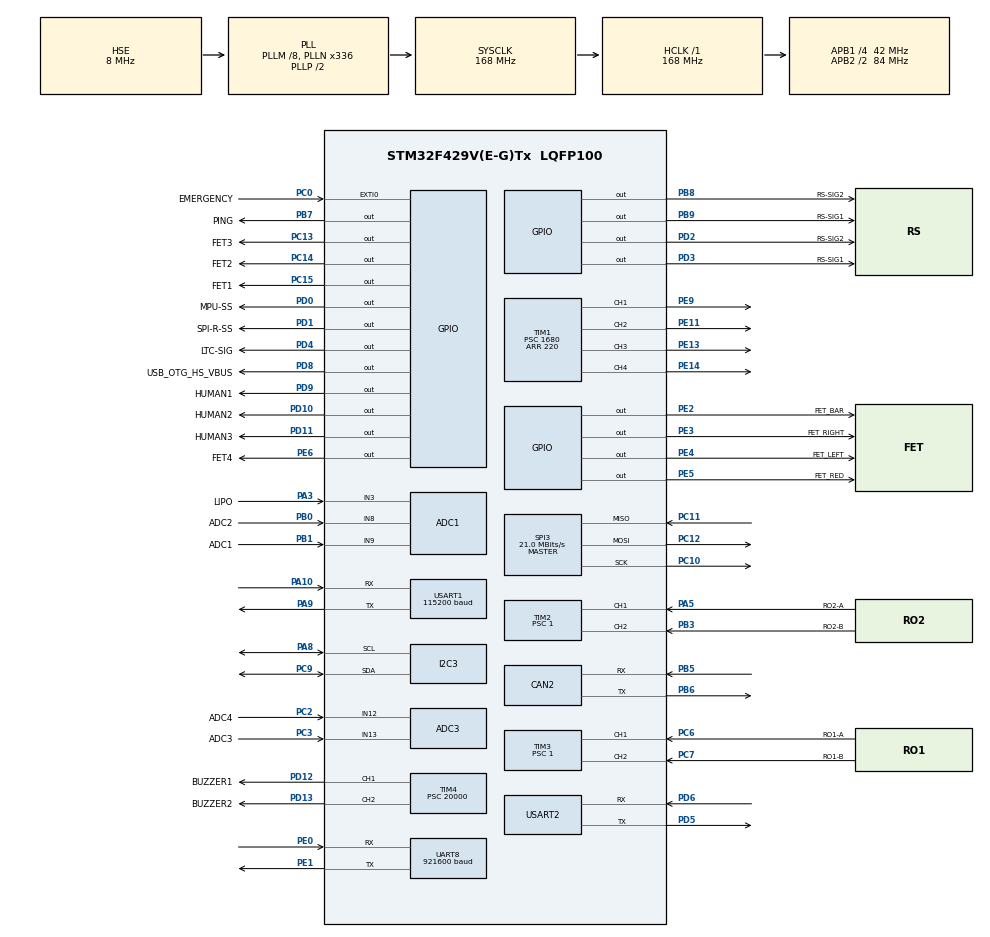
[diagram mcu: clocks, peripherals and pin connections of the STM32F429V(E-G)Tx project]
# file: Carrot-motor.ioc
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ADC1.Channel-3\#ChannelRegularConversion=ADC_CHANNEL_3
ADC1.Channel-6\#ChannelRegularConversion=ADC_CHANNEL_9
ADC1.ClockPrescaler=ADC_CLOCK_SYNC_PCLK_DIV4
ADC1.ContinuousConvMode=ENABLE
ADC1.DMAContinuousRequests=ENABLE
ADC1.InjNumberOfConversion=0
ADC1.NbrOfConversion=2
ADC1.NbrOfConversionFlag=1
ADC1.Rank-3\#ChannelRegularConversion=1
ADC1.Rank-6\#ChannelRegularConversion=2
ADC1.SamplingTime-3\#ChannelRegularConversion=ADC_SAMPLETIME_480CYCLES
ADC1.SamplingTime-6\#ChannelRegularConversion=ADC_SAMPLETIME_480CYCLES
ADC1.ScanConvMode=ENABLE
ADC1.master=1
ADC3.Channel-0\#ChannelRegularConversion=ADC_CHANNEL_12
ADC3.ClockPrescaler=ADC_CLOCK_SYNC_PCLK_DIV4
ADC3.NbrOfConversionFlag=1
ADC3.Rank-0\#ChannelRegularConversion=1
ADC3.SamplingTime-0\#ChannelRegularConversion=ADC_SAMPLETIME_3CYCLES
CAN2.BS1=CAN_BS1_1TQ
CAN2.BS2=CAN_BS2_1TQ
CAN2.CalculateTimeQuantum=380.95238095238096
Dma.ADC1.0.Direction=DMA_PERIPH_TO_MEMORY
Dma.ADC1.0.FIFOMode=DMA_FIFOMODE_DISABLE
Dma.ADC1.0.Instance=DMA2_Stream0
Dma.ADC1.0.MemDataAlignment=DMA_MDATAALIGN_HALFWORD
Dma.ADC1.0.MemInc=DMA_MINC_ENABLE
Dma.ADC1.0.Mode=DMA_CIRCULAR
Dma.ADC1.0.PeriphDataAlignment=DMA_PDATAALIGN_HALFWORD
Dma.ADC1.0.PeriphInc=DMA_PINC_DISABLE
Dma.ADC1.0.Priority=DMA_PRIORITY_HIGH
Dma.Request0=ADC1
Dma.Request1=UART8_RX
Dma.UART8_RX.1.Direction=DMA_PERIPH_TO_MEMORY
Dma.UART8_RX.1.FIFOMode=DMA_FIFOMODE_DISABLE
Dma.UART8_RX.1.Instance=DMA1_Stream6
Dma.UART8_RX.1.MemDataAlignment=DMA_MDATAALIGN_HALFWORD
Dma.UART8_RX.1.MemInc=DMA_MINC_ENABLE
Dma.UART8_RX.1.Mode=DMA_CIRCULAR
Dma.UART8_RX.1.PeriphDataAlignment=DMA_PDATAALIGN_HALFWORD
Dma.UART8_RX.1.PeriphInc=DMA_PINC_DISABLE
Dma.UART8_RX.1.Priority=DMA_PRIORITY_HIGH
FREERTOS.HEAP_NUMBER=4
FREERTOS.INCLUDE_uxTaskGetStackHighWaterMark=1
FREERTOS.INCLUDE_vTaskDelayUntil=1
FREERTOS.MEMORY_ALLOCATION=2
FREERTOS.Tasks01=defaultTask,8,128,StartDefaultTask,Default,NULL,Static,defaultTaskBuffer,defaultTaskControlBlock;adc1,8,1024,check_adc1_task,As external,NULL,Static,adc1Buffer,adc1ControlBlock;motor,8,1024,motor_task,As external,NULL,Static,motorBuffer,motorControlBlock;EMERGENCY,8,1024,EMERGENCY_notification,As external,NULL,Static,EMERGENCYBuffer,EMERGENCYControlBlock;encoder,48,128,encoder_task,As external,NULL,Static,encoderBuffer,encoderControlBlock;led,8,1024,led_task,As external,NULL,Static,LED_taskBuffer,LED_taskControlBlock
FREERTOS.configUSE_IDLE_HOOK=1
FREERTOS.configUSE_STATS_FORMATTING_FUNCTIONS=1
FREERTOS.configUSE_TRACE_FACILITY=1
Mcu.Family=STM32F4
Mcu.Name=STM32F429V(E-G)Tx
Mcu.Package=LQFP100
NVIC.DMA1_Stream6_IRQn=true\:5\:0\:false\:false\:true\:true\:false\:true
NVIC.DMA2_Stream0_IRQn=true\:5\:0\:false\:false\:true\:true\:false\:true
NVIC.EXTI0_IRQn=true\:2\:0\:true\:false\:true\:false\:true\:true
NVIC.PriorityGroup=NVIC_PRIORITYGROUP_4
NVIC.TIM1_UP_TIM10_IRQn=true\:5\:0\:false\:false\:true\:true\:true\:true
NVIC.TIM8_TRG_COM_TIM14_IRQn=true\:0\:0\:false\:false\:true\:false\:false\:true
NVIC.TIM8_UP_TIM13_IRQn=true\:5\:0\:false\:false\:true\:true\:true\:true
NVIC.TimeBase=TIM8_TRG_COM_TIM14_IRQn
NVIC.TimeBaseIP=TIM14
NVIC.UART8_IRQn=true\:1\:0\:true\:false\:true\:false\:true\:true
PA10.Mode=Asynchronous
PA10.Signal=USART1_RX
PA13.Mode=Serial_Wire
PA13.Signal=SYS_JTMS-SWDIO
PA14.Mode=Serial_Wire
PA14.Signal=SYS_JTCK-SWCLK
PA3.GPIO_Label=LIPO
PA3.Signal=ADCx_IN3
PA5.GPIO_Label=RO2-A
PA5.GPIO_Speed=GPIO_SPEED_FREQ_VERY_HIGH
PA5.Signal=S_TIM2_CH1_ETR
PA8.Mode=I2C
PA8.Signal=I2C3_SCL
PA9.Mode=Asynchronous
PA9.Signal=USART1_TX
PB0.GPIO_Label=ADC2
PB0.Signal=ADCx_IN8
PB1.GPIO_Label=ADC1
PB1.Signal=ADCx_IN9
PB14.Signal=USB_OTG_HS_DM
PB15.Signal=USB_OTG_HS_DP
PB3.GPIO_Label=RO2-B
PB3.GPIO_Speed=GPIO_SPEED_FREQ_VERY_HIGH
PB3.Signal=S_TIM2_CH2
PB5.Mode=Slave
PB5.Signal=CAN2_RX
PB6.Mode=Slave
PB6.Signal=CAN2_TX
PB7.GPIO_Label=PING
PB7.Signal=GPIO_Output
PB8.GPIO_Label=RS-SIG2
PB8.Signal=GPIO_Output
PB9.GPIO_Label=RS-SIG1
PB9.Signal=GPIO_Output
PC0.GPIO_Label=EMERGENCY
PC0.GPIO_ModeDefaultEXTI=GPIO_MODE_IT_RISING_FALLING
PC0.Signal=GPXTI0
PC10.Mode=Full_Duplex_Master
PC10.Signal=SPI3_SCK
PC11.Mode=Full_Duplex_Master
PC11.Signal=SPI3_MISO
PC12.Mode=Full_Duplex_Master
PC12.Signal=SPI3_MOSI
PC13.GPIO_Label=FET3
PC13.GPIO_PuPd=GPIO_NOPULL
PC13.PinState=GPIO_PIN_SET
PC13.Signal=GPIO_Output
PC14/OSC32_IN.GPIO_Label=FET2
PC14/OSC32_IN.GPIO_PuPd=GPIO_NOPULL
PC14/OSC32_IN.PinState=GPIO_PIN_SET
PC14/OSC32_IN.Signal=GPIO_Output
PC15/OSC32_OUT.GPIO_Label=FET1
PC15/OSC32_OUT.GPIO_PuPd=GPIO_NOPULL
PC15/OSC32_OUT.PinState=GPIO_PIN_SET
PC15/OSC32_OUT.Signal=GPIO_Output
PC2.GPIO_Label=ADC4
PC2.Signal=ADCx_IN12
PC3.GPIO_Label=ADC3
PC3.Signal=ADCx_IN13
PC6.GPIO_Label=RO1-A
PC6.GPIO_Speed=GPIO_SPEED_FREQ_VERY_HIGH
PC6.Signal=S_TIM3_CH1
PC7.GPIO_Label=RO1-B
PC7.GPIO_Speed=GPIO_SPEED_FREQ_VERY_HIGH
PC7.Signal=S_TIM3_CH2
PC9.Mode=I2C
PC9.Signal=I2C3_SDA
PD0.GPIO_Label=MPU-SS
PD0.Signal=GPIO_Output
PD1.GPIO_Label=SPI-R-SS
PD1.Signal=GPIO_Output
PD10.GPIO_Label=HUMAN2
PD10.Signal=GPIO_Output
PD11.GPIO_Label=HUMAN3
PD11.Signal=GPIO_Output
PD12.GPIO_Label=BUZZER1
PD12.Signal=S_TIM4_CH1
PD13.GPIO_Label=BUZZER2
PD13.Signal=S_TIM4_CH2
PD2.GPIO_Label=RS-SIG2
PD2.Signal=GPIO_Output
PD3.GPIO_Label=RS-SIG1
PD3.Signal=GPIO_Output
PD4.GPIO_Label=LTC-SIG
PD4.Signal=GPIO_Output
PD5.Mode=Asynchronous
PD5.Signal=USART2_TX
PD6.Mode=Asynchronous
PD6.Signal=USART2_RX
PD8.GPIO_Label=USB_OTG_HS_VBUS
PD8.Signal=GPIO_Output
PD9.GPIO_Label=HUMAN1
PD9.Signal=GPIO_Output
PE0.Mode=Asynchronous
PE0.Signal=UART8_RX
PE1.Mode=Asynchronous
PE1.Signal=UART8_TX
PE11.Signal=S_TIM1_CH2
PE13.Signal=S_TIM1_CH3
PE14.Signal=S_TIM1_CH4
PE2.GPIO_Label=FET_BAR
PE2.PinState=GPIO_PIN_SET
PE2.Signal=GPIO_Output
PE3.GPIO_Label=FET_RIGHT
PE3.PinState=GPIO_PIN_SET
PE3.Signal=GPIO_Output
PE4.GPIO_Label=FET_LEFT
PE4.PinState=GPIO_PIN_SET
PE4.Signal=GPIO_Output
PE5.GPIO_Label=FET_RED
PE5.PinState=GPIO_PIN_SET
PE5.Signal=GPIO_Output
PE6.GPIO_Label=FET4
PE6.GPIO_Speed=GPIO_SPEED_FREQ_VERY_HIGH
PE6.PinState=GPIO_PIN_SET
PE6.Signal=GPIO_Output
PE9.GPIO_Speed=GPIO_SPEED_FREQ_LOW
PE9.Signal=S_TIM1_CH1
PH0/OSC_IN.Mode=HSE-External-Oscillator
PH0/OSC_IN.Signal=RCC_OSC_IN
PH1/OSC_OUT.Mode=HSE-External-Oscillator
PH1/OSC_OUT.Signal=RCC_OSC_OUT
ProjectManager.HeapSize=0x200
ProjectManager.StackSize=0x400
ProjectManager.TargetToolchain=STM32CubeIDE
RCC.48MHZClocksFreq_Value=48000000
RCC.AHBFreq_Value=168000000
RCC.APB1CLKDivider=RCC_HCLK_DIV4
RCC.APB1Freq_Value=42000000
RCC.APB1TimFreq_Value=84000000
RCC.APB2CLKDivider=RCC_HCLK_DIV2
RCC.APB2Freq_Value=84000000
RCC.APB2TimFreq_Value=168000000
RCC.CortexFreq_Value=168000000
RCC.HCLKFreq_Value=168000000
RCC.HSE_VALUE=8000000
RCC.HSI_VALUE=16000000
RCC.LSE_VALUE=32768
RCC.PLLM=8
RCC.PLLN=336
RCC.PLLQ=7
RCC.PLLSourceVirtual=RCC_PLLSOURCE_HSE
RCC.SYSCLKFreq_VALUE=168000000
RCC.SYSCLKSource=RCC_SYSCLKSOURCE_PLLCLK
RCC.VCOOutputFreq_Value=336000000
SH.ADCx_IN12.0=ADC3_IN12,IN12
SH.ADCx_IN13.0=ADC3_IN13,IN13
SH.ADCx_IN3.0=ADC1_IN3,IN3
SH.ADCx_IN8.0=ADC1_IN8,IN8
SH.ADCx_IN9.0=ADC1_IN9,IN9
SH.S_TIM1_CH1.0=TIM1_CH1,PWM Generation1 CH1
SH.S_TIM1_CH2.0=TIM1_CH2,PWM Generation2 CH2
SH.S_TIM1_CH3.0=TIM1_CH3,PWM Generation3 CH3
SH.S_TIM1_CH4.0=TIM1_CH4,PWM Generation4 CH4
SH.S_TIM2_CH1_ETR.0=TIM2_CH1,Encoder_Interface
SH.S_TIM2_CH2.0=TIM2_CH2,Encoder_Interface
SH.S_TIM3_CH1.0=TIM3_CH1,Encoder_Interface
SH.S_TIM3_CH2.0=TIM3_CH2,Encoder_Interface
SH.S_TIM4_CH1.0=TIM4_CH1,PWM Generation1 CH1
SH.S_TIM4_CH2.0=TIM4_CH2,PWM Generation2 CH2
SPI3.BaudRatePrescaler=SPI_BAUDRATEPRESCALER_2
SPI3.CalculateBaudRate=21.0 MBits/s
SPI3.Direction=SPI_DIRECTION_2LINES
SPI3.Mode=SPI_MODE_MASTER
SPI3.VirtualType=VM_MASTER
TIM1.Channel-PWM\ Generation1\ CH1=TIM_CHANNEL_1
TIM1.Channel-PWM\ Generation2\ CH2=TIM_CHANNEL_2
TIM1.Channel-PWM\ Generation3\ CH3=TIM_CHANNEL_3
TIM1.Channel-PWM\ Generation4\ CH4=TIM_CHANNEL_4
TIM1.Period=220
TIM1.Prescaler=1680
TIM10.Period=1
TIM10.Prescaler=0
TIM13.Period=1
TIM13.Prescaler=0
TIM2.Period=65535
TIM2.Prescaler=1
TIM3.AutoReloadPreload=TIM_AUTORELOAD_PRELOAD_DISABLE
TIM3.Period=65535
TIM3.Prescaler=1
TIM3.TIM_MasterOutputTrigger=TIM_TRGO_RESET
TIM3.TIM_MasterSlaveMode=TIM_MASTERSLAVEMODE_DISABLE
TIM4.Channel-PWM\ Generation1\ CH1=TIM_CHANNEL_1
TIM4.Channel-PWM\ Generation2\ CH2=TIM_CHANNEL_2
TIM4.ClockDivision=TIM_CLOCKDIVISION_DIV1
TIM4.Period=10
TIM4.Prescaler=20000
UART8.BaudRate=921600
UART8.VirtualMode=Asynchronous
USART1.BaudRate=115200
USART1.Parity=PARITY_NONE
USART1.VirtualMode=VM_ASYNC
USART2.VirtualMode=VM_ASYNC
VP_FREERTOS_VS_CMSIS_V2.Mode=CMSIS_V2
VP_SYS_VS_tim14.Mode=TIM14
VP_TIM10_VS_ClockSourceINT.Mode=Enable_Timer
VP_TIM13_VS_ClockSourceINT.Mode=Enable_Timer
board=custom

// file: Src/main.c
/* USER CODE BEGIN Header */
/**
  ******************************************************************************
  * @file           : main.c
  * @brief          : Main program body
  ******************************************************************************
  * @attention
  *
  * <h2><center>&copy; Copyright (c) 2019 STMicroelectronics.
  * All rights reserved.</center></h2>
  *
  * This software component is licensed by ST under BSD 3-Clause license,
  * the "License"; You may not use this file except in compliance with the
  * License. You may obtain a copy of the License at:
  *                        opensource.org/licenses/BSD-3-Clause
  *
  ******************************************************************************
  */
/* USER CODE END Header */

#include "main.h"
#include "cmsis_os.h"

/* USER CODE BEGIN Includes */
#include "source/carrot_adc_control.hpp"
#include "source/carrot_wrapper.hpp"
#include "source/interrupt.hpp"
#include "source/motor_control.hpp"
/* USER CODE END Includes */

typedef StaticTask_t osStaticThreadDef_t;

ADC_HandleTypeDef hadc1;
ADC_HandleTypeDef hadc3;
DMA_HandleTypeDef hdma_adc1;

CAN_HandleTypeDef hcan2;

I2C_HandleTypeDef hi2c3;

SPI_HandleTypeDef hspi3;

TIM_HandleTypeDef htim1;
TIM_HandleTypeDef htim2;
TIM_HandleTypeDef htim3;
TIM_HandleTypeDef htim4;
TIM_HandleTypeDef htim10;
TIM_HandleTypeDef htim13;

UART_HandleTypeDef huart8;
UART_HandleTypeDef huart1;
UART_HandleTypeDef huart2;
DMA_HandleTypeDef hdma_uart8_rx;

/* Definitions for defaultTask */
osThreadId_t defaultTaskHandle;
uint32_t defaultTaskBuffer[ 128 ];
osStaticThreadDef_t defaultTaskControlBlock;
const osThreadAttr_t defaultTask_attributes = {
  .name = "defaultTask",
  .stack_mem = &defaultTaskBuffer[0],
  .stack_size = sizeof(defaultTaskBuffer),
  .cb_mem = &defaultTaskControlBlock,
  .cb_size = sizeof(defaultTaskControlBlock),
  .priority = (osPriority_t) osPriorityLow,
};
/* Definitions for adc1 */
osThreadId_t adc1Handle;
uint32_t adc1Buffer[ 1024 ];
osStaticThreadDef_t adc1ControlBlock;
const osThreadAttr_t adc1_attributes = {
  .name = "adc1",
  .stack_mem = &adc1Buffer[0],
  .stack_size = sizeof(adc1Buffer),
  .cb_mem = &adc1ControlBlock,
  .cb_size = sizeof(adc1ControlBlock),
  .priority = (osPriority_t) osPriorityLow,
};
/* Definitions for motor */
osThreadId_t motorHandle;
uint32_t motorBuffer[ 1024 ];
osStaticThreadDef_t motorControlBlock;
const osThreadAttr_t motor_attributes = {
  .name = "motor",
  .stack_mem = &motorBuffer[0],
  .stack_size = sizeof(motorBuffer),
  .cb_mem = &motorControlBlock,
  .cb_size = sizeof(motorControlBlock),
  .priority = (osPriority_t) osPriorityLow,
};
/* Definitions for EMERGENCY */
osThreadId_t EMERGENCYHandle;
uint32_t EMERGENCYBuffer[ 1024 ];
osStaticThreadDef_t EMERGENCYControlBlock;
const osThreadAttr_t EMERGENCY_attributes = {
  .name = "EMERGENCY",
  .stack_mem = &EMERGENCYBuffer[0],
  .stack_size = sizeof(EMERGENCYBuffer),
  .cb_mem = &EMERGENCYControlBlock,
  .cb_size = sizeof(EMERGENCYControlBlock),
  .priority = (osPriority_t) osPriorityLow,
};
/* Definitions for encoder */
osThreadId_t encoderHandle;
uint32_t encoderBuffer[ 128 ];
osStaticThreadDef_t encoderControlBlock;
const osThreadAttr_t encoder_attributes = {
  .name = "encoder",
  .stack_mem = &encoderBuffer[0],
  .stack_size = sizeof(encoderBuffer),
  .cb_mem = &encoderControlBlock,
  .cb_size = sizeof(encoderControlBlock),
  .priority = (osPriority_t) osPriorityRealtime,
};
/* Definitions for led */
osThreadId_t ledHandle;
uint32_t LED_taskBuffer[ 1024 ];
osStaticThreadDef_t LED_taskControlBlock;
const osThreadAttr_t led_attributes = {
  .name = "led",
  .stack_mem = &LED_taskBuffer[0],
  .stack_size = sizeof(LED_taskBuffer),
  .cb_mem = &LED_taskControlBlock,
  .cb_size = sizeof(LED_taskControlBlock),
  .priority = (osPriority_t) osPriorityLow,
};

void SystemClock_Config(void);
static void MX_GPIO_Init(void);
static void MX_DMA_Init(void);
static void MX_USART1_UART_Init(void);
static void MX_USART2_UART_Init(void);
static void MX_CAN2_Init(void);
static void MX_SPI3_Init(void);
static void MX_TIM1_Init(void);
static void MX_TIM2_Init(void);
static void MX_ADC1_Init(void);
static void MX_ADC3_Init(void);
static void MX_TIM3_Init(void);
static void MX_TIM4_Init(void);
static void MX_UART8_Init(void);
static void MX_I2C3_Init(void);
static void MX_TIM13_Init(void);
static void MX_TIM10_Init(void);
void StartDefaultTask(void *argument);
extern void check_adc1_task(void *argument);
extern void motor_task(void *argument);
extern void EMERGENCY_notification(void *argument);
extern void encoder_task(void *argument);
extern void led_task(void *argument);

/* USER CODE BEGIN 0 */
void HAL_UART_RxCpltCallback(UART_HandleTypeDef *UartHandle)
{
     /*if(UartHandle->Instance==UART8){
    	 raspi_uart_func();
    }*/
}

/* USER CODE END 0 */

int main(void)
{

  /* MCU Configuration--------------------------------------------------------*/

  /* Reset of all peripherals, Initializes the Flash interface and the Systick. */
  HAL_Init();

  /* Configure the system clock */
  SystemClock_Config();

  /* Initialize all configured peripherals */
  MX_GPIO_Init();
  MX_DMA_Init();
  MX_USART1_UART_Init();
  MX_USART2_UART_Init();
  MX_CAN2_Init();
  MX_SPI3_Init();
  MX_TIM1_Init();
  MX_TIM2_Init();
  MX_ADC1_Init();
  MX_ADC3_Init();
  MX_TIM3_Init();
  MX_TIM4_Init();
  MX_UART8_Init();
  MX_I2C3_Init();
  MX_TIM13_Init();
  MX_TIM10_Init();
  /* USER CODE BEGIN 2 */
  init_carrot();

  /* USER CODE END 2 */
  /* Init scheduler */
  osKernelInitialize();

  /* Create the thread(s) */
  /* creation of defaultTask */
  defaultTaskHandle = osThreadNew(StartDefaultTask, NULL, &defaultTask_attributes);

  /* creation of adc1 */
  adc1Handle = osThreadNew(check_adc1_task, NULL, &adc1_attributes);

  /* creation of motor */
  motorHandle = osThreadNew(motor_task, NULL, &motor_attributes);

  /* creation of EMERGENCY */
  EMERGENCYHandle = osThreadNew(EMERGENCY_notification, NULL, &EMERGENCY_attributes);

  /* creation of encoder */
  encoderHandle = osThreadNew(encoder_task, NULL, &encoder_attributes);

  /* creation of led */
  ledHandle = osThreadNew(led_task, NULL, &led_attributes);

  /* Start scheduler */
  osKernelStart();

  /* We should never get here as control is now taken by the scheduler */

  /* Infinite loop */
  while (1)
  {

  }
}

void SystemClock_Config(void)
{
  RCC_OscInitTypeDef RCC_OscInitStruct = {0};
  RCC_ClkInitTypeDef RCC_ClkInitStruct = {0};

  /** Configure the main internal regulator output voltage
  */
  __HAL_RCC_PWR_CLK_ENABLE();
  __HAL_PWR_VOLTAGESCALING_CONFIG(PWR_REGULATOR_VOLTAGE_SCALE1);
  /** Initializes the CPU, AHB and APB busses clocks
  */
  RCC_OscInitStruct.OscillatorType = RCC_OSCILLATORTYPE_HSE;
  RCC_OscInitStruct.HSEState = RCC_HSE_ON;
  RCC_OscInitStruct.PLL.PLLState = RCC_PLL_ON;
  RCC_OscInitStruct.PLL.PLLSource = RCC_PLLSOURCE_HSE;
  RCC_OscInitStruct.PLL.PLLM = 8;
  RCC_OscInitStruct.PLL.PLLN = 336;
  RCC_OscInitStruct.PLL.PLLP = RCC_PLLP_DIV2;
  RCC_OscInitStruct.PLL.PLLQ = 7;
  if (HAL_RCC_OscConfig(&RCC_OscInitStruct) != HAL_OK)
  {
    Error_Handler();
  }
  /** Initializes the CPU, AHB and APB busses clocks
  */
  RCC_ClkInitStruct.ClockType = RCC_CLOCKTYPE_HCLK|RCC_CLOCKTYPE_SYSCLK
                              |RCC_CLOCKTYPE_PCLK1|RCC_CLOCKTYPE_PCLK2;
  RCC_ClkInitStruct.SYSCLKSource = RCC_SYSCLKSOURCE_PLLCLK;
  RCC_ClkInitStruct.AHBCLKDivider = RCC_SYSCLK_DIV1;
  RCC_ClkInitStruct.APB1CLKDivider = RCC_HCLK_DIV4;
  RCC_ClkInitStruct.APB2CLKDivider = RCC_HCLK_DIV2;

  if (HAL_RCC_ClockConfig(&RCC_ClkInitStruct, FLASH_LATENCY_5) != HAL_OK)
  {
    Error_Handler();
  }
}

static void MX_ADC1_Init(void)
{

  ADC_ChannelConfTypeDef sConfig = {0};

  /** Configure the global features of the ADC (Clock, Resolution, Data Alignment and number of conversion)
  */
  hadc1.Instance = ADC1;
  hadc1.Init.ClockPrescaler = ADC_CLOCK_SYNC_PCLK_DIV4;
  hadc1.Init.Resolution = ADC_RESOLUTION_12B;
  hadc1.Init.ScanConvMode = ENABLE;
  hadc1.Init.ContinuousConvMode = ENABLE;
  hadc1.Init.DiscontinuousConvMode = DISABLE;
  hadc1.Init.ExternalTrigConvEdge = ADC_EXTERNALTRIGCONVEDGE_NONE;
  hadc1.Init.ExternalTrigConv = ADC_SOFTWARE_START;
  hadc1.Init.DataAlign = ADC_DATAALIGN_RIGHT;
  hadc1.Init.NbrOfConversion = 2;
  hadc1.Init.DMAContinuousRequests = ENABLE;
  hadc1.Init.EOCSelection = ADC_EOC_SINGLE_CONV;
  if (HAL_ADC_Init(&hadc1) != HAL_OK)
  {
    Error_Handler();
  }
  /** Configure for the selected ADC regular channel its corresponding rank in the sequencer and its sample time.
  */
  sConfig.Channel = ADC_CHANNEL_3;
  sConfig.Rank = 1;
  sConfig.SamplingTime = ADC_SAMPLETIME_480CYCLES;
  if (HAL_ADC_ConfigChannel(&hadc1, &sConfig) != HAL_OK)
  {
    Error_Handler();
  }
  /** Configure for the selected ADC regular channel its corresponding rank in the sequencer and its sample time.
  */
  sConfig.Channel = ADC_CHANNEL_9;
  sConfig.Rank = 2;
  if (HAL_ADC_ConfigChannel(&hadc1, &sConfig) != HAL_OK)
  {
    Error_Handler();
  }

}

static void MX_ADC3_Init(void)
{

  ADC_ChannelConfTypeDef sConfig = {0};

  /** Configure the global features of the ADC (Clock, Resolution, Data Alignment and number of conversion)
  */
  hadc3.Instance = ADC3;
  hadc3.Init.ClockPrescaler = ADC_CLOCK_SYNC_PCLK_DIV4;
  hadc3.Init.Resolution = ADC_RESOLUTION_12B;
  hadc3.Init.ScanConvMode = DISABLE;
  hadc3.Init.ContinuousConvMode = DISABLE;
  hadc3.Init.DiscontinuousConvMode = DISABLE;
  hadc3.Init.ExternalTrigConvEdge = ADC_EXTERNALTRIGCONVEDGE_NONE;
  hadc3.Init.ExternalTrigConv = ADC_SOFTWARE_START;
  hadc3.Init.DataAlign = ADC_DATAALIGN_RIGHT;
  hadc3.Init.NbrOfConversion = 1;
  hadc3.Init.DMAContinuousRequests = DISABLE;
  hadc3.Init.EOCSelection = ADC_EOC_SINGLE_CONV;
  if (HAL_ADC_Init(&hadc3) != HAL_OK)
  {
    Error_Handler();
  }
  /** Configure for the selected ADC regular channel its corresponding rank in the sequencer and its sample time.
  */
  sConfig.Channel = ADC_CHANNEL_12;
  sConfig.Rank = 1;
  sConfig.SamplingTime = ADC_SAMPLETIME_3CYCLES;
  if (HAL_ADC_ConfigChannel(&hadc3, &sConfig) != HAL_OK)
  {
    Error_Handler();
  }

}

static void MX_CAN2_Init(void)
{

  hcan2.Instance = CAN2;
  hcan2.Init.Prescaler = 16;
  hcan2.Init.Mode = CAN_MODE_NORMAL;
  hcan2.Init.SyncJumpWidth = CAN_SJW_1TQ;
  hcan2.Init.TimeSeg1 = CAN_BS1_1TQ;
  hcan2.Init.TimeSeg2 = CAN_BS2_1TQ;
  hcan2.Init.TimeTriggeredMode = DISABLE;
  hcan2.Init.AutoBusOff = DISABLE;
  hcan2.Init.AutoWakeUp = DISABLE;
  hcan2.Init.AutoRetransmission = DISABLE;
  hcan2.Init.ReceiveFifoLocked = DISABLE;
  hcan2.Init.TransmitFifoPriority = DISABLE;
  if (HAL_CAN_Init(&hcan2) != HAL_OK)
  {
    Error_Handler();
  }

}

static void MX_I2C3_Init(void)
{

  hi2c3.Instance = I2C3;
  hi2c3.Init.ClockSpeed = 100000;
  hi2c3.Init.DutyCycle = I2C_DUTYCYCLE_2;
  hi2c3.Init.OwnAddress1 = 0;
  hi2c3.Init.AddressingMode = I2C_ADDRESSINGMODE_7BIT;
  hi2c3.Init.DualAddressMode = I2C_DUALADDRESS_DISABLE;
  hi2c3.Init.OwnAddress2 = 0;
  hi2c3.Init.GeneralCallMode = I2C_GENERALCALL_DISABLE;
  hi2c3.Init.NoStretchMode = I2C_NOSTRETCH_DISABLE;
  if (HAL_I2C_Init(&hi2c3) != HAL_OK)
  {
    Error_Handler();
  }
  /** Configure Analogue filter
  */
  if (HAL_I2CEx_ConfigAnalogFilter(&hi2c3, I2C_ANALOGFILTER_ENABLE) != HAL_OK)
  {
    Error_Handler();
  }
  /** Configure Digital filter
  */
  if (HAL_I2CEx_ConfigDigitalFilter(&hi2c3, 0) != HAL_OK)
  {
    Error_Handler();
  }

}

static void MX_SPI3_Init(void)
{

  /* SPI3 parameter configuration*/
  hspi3.Instance = SPI3;
  hspi3.Init.Mode = SPI_MODE_MASTER;
  hspi3.Init.Direction = SPI_DIRECTION_2LINES;
  hspi3.Init.DataSize = SPI_DATASIZE_8BIT;
  hspi3.Init.CLKPolarity = SPI_POLARITY_LOW;
  hspi3.Init.CLKPhase = SPI_PHASE_1EDGE;
  hspi3.Init.NSS = SPI_NSS_SOFT;
  hspi3.Init.BaudRatePrescaler = SPI_BAUDRATEPRESCALER_2;
  hspi3.Init.FirstBit = SPI_FIRSTBIT_MSB;
  hspi3.Init.TIMode = SPI_TIMODE_DISABLE;
  hspi3.Init.CRCCalculation = SPI_CRCCALCULATION_DISABLE;
  hspi3.Init.CRCPolynomial = 10;
  if (HAL_SPI_Init(&hspi3) != HAL_OK)
  {
    Error_Handler();
  }

}

static void MX_TIM1_Init(void)
{

  TIM_MasterConfigTypeDef sMasterConfig = {0};
  TIM_OC_InitTypeDef sConfigOC = {0};
  TIM_BreakDeadTimeConfigTypeDef sBreakDeadTimeConfig = {0};

  htim1.Instance = TIM1;
  htim1.Init.Prescaler = 1680;
  htim1.Init.CounterMode = TIM_COUNTERMODE_UP;
  htim1.Init.Period = 220;
  htim1.Init.ClockDivision = TIM_CLOCKDIVISION_DIV1;
  htim1.Init.RepetitionCounter = 0;
  htim1.Init.AutoReloadPreload = TIM_AUTORELOAD_PRELOAD_DISABLE;
  if (HAL_TIM_PWM_Init(&htim1) != HAL_OK)
  {
    Error_Handler();
  }
  sMasterConfig.MasterOutputTrigger = TIM_TRGO_RESET;
  sMasterConfig.MasterSlaveMode = TIM_MASTERSLAVEMODE_DISABLE;
  if (HAL_TIMEx_MasterConfigSynchronization(&htim1, &sMasterConfig) != HAL_OK)
  {
    Error_Handler();
  }
  sConfigOC.OCMode = TIM_OCMODE_PWM1;
  sConfigOC.Pulse = 0;
  sConfigOC.OCPolarity = TIM_OCPOLARITY_HIGH;
  sConfigOC.OCNPolarity = TIM_OCNPOLARITY_HIGH;
  sConfigOC.OCFastMode = TIM_OCFAST_DISABLE;
  sConfigOC.OCIdleState = TIM_OCIDLESTATE_RESET;
  sConfigOC.OCNIdleState = TIM_OCNIDLESTATE_RESET;
  if (HAL_TIM_PWM_ConfigChannel(&htim1, &sConfigOC, TIM_CHANNEL_1) != HAL_OK)
  {
    Error_Handler();
  }
  if (HAL_TIM_PWM_ConfigChannel(&htim1, &sConfigOC, TIM_CHANNEL_2) != HAL_OK)
  {
    Error_Handler();
  }
  if (HAL_TIM_PWM_ConfigChannel(&htim1, &sConfigOC, TIM_CHANNEL_3) != HAL_OK)
  {
    Error_Handler();
  }
  if (HAL_TIM_PWM_ConfigChannel(&htim1, &sConfigOC, TIM_CHANNEL_4) != HAL_OK)
  {
    Error_Handler();
  }
  sBreakDeadTimeConfig.OffStateRunMode = TIM_OSSR_DISABLE;
  sBreakDeadTimeConfig.OffStateIDLEMode = TIM_OSSI_DISABLE;
  sBreakDeadTimeConfig.LockLevel = TIM_LOCKLEVEL_OFF;
  sBreakDeadTimeConfig.DeadTime = 0;
  sBreakDeadTimeConfig.BreakState = TIM_BREAK_DISABLE;
  sBreakDeadTimeConfig.BreakPolarity = TIM_BREAKPOLARITY_HIGH;
  sBreakDeadTimeConfig.AutomaticOutput = TIM_AUTOMATICOUTPUT_DISABLE;
  if (HAL_TIMEx_ConfigBreakDeadTime(&htim1, &sBreakDeadTimeConfig) != HAL_OK)
  {
    Error_Handler();
  }
  HAL_TIM_MspPostInit(&htim1);

}

static void MX_TIM2_Init(void)
{

  TIM_Encoder_InitTypeDef sConfig = {0};
  TIM_MasterConfigTypeDef sMasterConfig = {0};

  htim2.Instance = TIM2;
  htim2.Init.Prescaler = 1;
  htim2.Init.CounterMode = TIM_COUNTERMODE_UP;
  htim2.Init.Period = 65535;
  htim2.Init.ClockDivision = TIM_CLOCKDIVISION_DIV1;
  htim2.Init.AutoReloadPreload = TIM_AUTORELOAD_PRELOAD_DISABLE;
  sConfig.EncoderMode = TIM_ENCODERMODE_TI1;
  sConfig.IC1Polarity = TIM_ICPOLARITY_RISING;
  sConfig.IC1Selection = TIM_ICSELECTION_DIRECTTI;
  sConfig.IC1Prescaler = TIM_ICPSC_DIV1;
  sConfig.IC1Filter = 0;
  sConfig.IC2Polarity = TIM_ICPOLARITY_RISING;
  sConfig.IC2Selection = TIM_ICSELECTION_DIRECTTI;
  sConfig.IC2Prescaler = TIM_ICPSC_DIV1;
  sConfig.IC2Filter = 0;
  if (HAL_TIM_Encoder_Init(&htim2, &sConfig) != HAL_OK)
  {
    Error_Handler();
  }
  sMasterConfig.MasterOutputTrigger = TIM_TRGO_RESET;
  sMasterConfig.MasterSlaveMode = TIM_MASTERSLAVEMODE_DISABLE;
  if (HAL_TIMEx_MasterConfigSynchronization(&htim2, &sMasterConfig) != HAL_OK)
  {
    Error_Handler();
  }

}

static void MX_TIM3_Init(void)
{

  TIM_Encoder_InitTypeDef sConfig = {0};
  TIM_MasterConfigTypeDef sMasterConfig = {0};

  htim3.Instance = TIM3;
  htim3.Init.Prescaler = 1;
  htim3.Init.CounterMode = TIM_COUNTERMODE_UP;
  htim3.Init.Period = 65535;
  htim3.Init.ClockDivision = TIM_CLOCKDIVISION_DIV1;
  htim3.Init.AutoReloadPreload = TIM_AUTORELOAD_PRELOAD_DISABLE;
  sConfig.EncoderMode = TIM_ENCODERMODE_TI1;
  sConfig.IC1Polarity = TIM_ICPOLARITY_RISING;
  sConfig.IC1Selection = TIM_ICSELECTION_DIRECTTI;
  sConfig.IC1Prescaler = TIM_ICPSC_DIV1;
  sConfig.IC1Filter = 0;
  sConfig.IC2Polarity = TIM_ICPOLARITY_RISING;
  sConfig.IC2Selection = TIM_ICSELECTION_DIRECTTI;
  sConfig.IC2Prescaler = TIM_ICPSC_DIV1;
  sConfig.IC2Filter = 0;
  if (HAL_TIM_Encoder_Init(&htim3, &sConfig) != HAL_OK)
  {
    Error_Handler();
  }
  sMasterConfig.MasterOutputTrigger = TIM_TRGO_RESET;
  sMasterConfig.MasterSlaveMode = TIM_MASTERSLAVEMODE_DISABLE;
  if (HAL_TIMEx_MasterConfigSynchronization(&htim3, &sMasterConfig) != HAL_OK)
  {
    Error_Handler();
  }

}

static void MX_TIM4_Init(void)
{

  TIM_MasterConfigTypeDef sMasterConfig = {0};
  TIM_OC_InitTypeDef sConfigOC = {0};

  htim4.Instance = TIM4;
  htim4.Init.Prescaler = 20000;
  htim4.Init.CounterMode = TIM_COUNTERMODE_UP;
  htim4.Init.Period = 10;
  htim4.Init.ClockDivision = TIM_CLOCKDIVISION_DIV1;
  htim4.Init.AutoReloadPreload = TIM_AUTORELOAD_PRELOAD_DISABLE;
  if (HAL_TIM_PWM_Init(&htim4) != HAL_OK)
  {
    Error_Handler();
  }
  sMasterConfig.MasterOutputTrigger = TIM_TRGO_RESET;
  sMasterConfig.MasterSlaveMode = TIM_MASTERSLAVEMODE_DISABLE;
  if (HAL_TIMEx_MasterConfigSynchronization(&htim4, &sMasterConfig) != HAL_OK)
  {
    Error_Handler();
  }
  sConfigOC.OCMode = TIM_OCMODE_PWM1;
  sConfigOC.Pulse = 0;
  sConfigOC.OCPolarity = TIM_OCPOLARITY_HIGH;
  sConfigOC.OCFastMode = TIM_OCFAST_DISABLE;
  if (HAL_TIM_PWM_ConfigChannel(&htim4, &sConfigOC, TIM_CHANNEL_1) != HAL_OK)
  {
    Error_Handler();
  }
  if (HAL_TIM_PWM_ConfigChannel(&htim4, &sConfigOC, TIM_CHANNEL_2) != HAL_OK)
  {
    Error_Handler();
  }
  HAL_TIM_MspPostInit(&htim4);

}

static void MX_TIM10_Init(void)
{

  htim10.Instance = TIM10;
  htim10.Init.Prescaler = 0;
  htim10.Init.CounterMode = TIM_COUNTERMODE_UP;
  htim10.Init.Period = 1;
  htim10.Init.ClockDivision = TIM_CLOCKDIVISION_DIV1;
  htim10.Init.AutoReloadPreload = TIM_AUTORELOAD_PRELOAD_DISABLE;
  if (HAL_TIM_Base_Init(&htim10) != HAL_OK)
  {
    Error_Handler();
  }

}

static void MX_TIM13_Init(void)
{

  htim13.Instance = TIM13;
  htim13.Init.Prescaler = 0;
  htim13.Init.CounterMode = TIM_COUNTERMODE_UP;
  htim13.Init.Period = 1;
  htim13.Init.ClockDivision = TIM_CLOCKDIVISION_DIV1;
  htim13.Init.AutoReloadPreload = TIM_AUTORELOAD_PRELOAD_DISABLE;
  if (HAL_TIM_Base_Init(&htim13) != HAL_OK)
  {
    Error_Handler();
  }

}

static void MX_UART8_Init(void)
{

  huart8.Instance = UART8;
  huart8.Init.BaudRate = 921600;
  huart8.Init.WordLength = UART_WORDLENGTH_8B;
  huart8.Init.StopBits = UART_STOPBITS_1;
  huart8.Init.Parity = UART_PARITY_NONE;
  huart8.Init.Mode = UART_MODE_TX_RX;
  huart8.Init.HwFlowCtl = UART_HWCONTROL_NONE;
  huart8.Init.OverSampling = UART_OVERSAMPLING_16;
  if (HAL_UART_Init(&huart8) != HAL_OK)
  {
    Error_Handler();
  }

}

static void MX_USART1_UART_Init(void)
{

  huart1.Instance = USART1;
  huart1.Init.BaudRate = 115200;
  huart1.Init.WordLength = UART_WORDLENGTH_8B;
  huart1.Init.StopBits = UART_STOPBITS_1;
  huart1.Init.Parity = UART_PARITY_NONE;
  huart1.Init.Mode = UART_MODE_TX_RX;
  huart1.Init.HwFlowCtl = UART_HWCONTROL_NONE;
  huart1.Init.OverSampling = UART_OVERSAMPLING_16;
  if (HAL_UART_Init(&huart1) != HAL_OK)
  {
    Error_Handler();
  }

}

static void MX_USART2_UART_Init(void)
{

  huart2.Instance = USART2;
  huart2.Init.BaudRate = 115200;
  huart2.Init.WordLength = UART_WORDLENGTH_8B;
  huart2.Init.StopBits = UART_STOPBITS_1;
  huart2.Init.Parity = UART_PARITY_NONE;
  huart2.Init.Mode = UART_MODE_TX_RX;
  huart2.Init.HwFlowCtl = UART_HWCONTROL_NONE;
  huart2.Init.OverSampling = UART_OVERSAMPLING_16;
  if (HAL_UART_Init(&huart2) != HAL_OK)
  {
    Error_Handler();
  }

}

static void MX_DMA_Init(void)
{

  /* DMA controller clock enable */
  __HAL_RCC_DMA2_CLK_ENABLE();
  __HAL_RCC_DMA1_CLK_ENABLE();

  /* DMA interrupt init */
  /* DMA1_Stream6_IRQn interrupt configuration */
  HAL_NVIC_SetPriority(DMA1_Stream6_IRQn, 5, 0);
  HAL_NVIC_EnableIRQ(DMA1_Stream6_IRQn);
  /* DMA2_Stream0_IRQn interrupt configuration */
  HAL_NVIC_SetPriority(DMA2_Stream0_IRQn, 5, 0);
  HAL_NVIC_EnableIRQ(DMA2_Stream0_IRQn);

}

static void MX_GPIO_Init(void)
{
  GPIO_InitTypeDef GPIO_InitStruct = {0};

  /* GPIO Ports Clock Enable */
  __HAL_RCC_GPIOE_CLK_ENABLE();
  __HAL_RCC_GPIOC_CLK_ENABLE();
  __HAL_RCC_GPIOH_CLK_ENABLE();
  __HAL_RCC_GPIOA_CLK_ENABLE();
  __HAL_RCC_GPIOB_CLK_ENABLE();
  __HAL_RCC_GPIOD_CLK_ENABLE();

  /*Configure GPIO pin Output Level */
  HAL_GPIO_WritePin(GPIOE, FET_BAR_Pin|FET_RIGHT_Pin|FET_LEFT_Pin|FET_RED_Pin
                          |FET4_Pin, GPIO_PIN_SET);

  /*Configure GPIO pin Output Level */
  HAL_GPIO_WritePin(GPIOC, FET3_Pin|FET2_Pin|FET1_Pin, GPIO_PIN_SET);

  /*Configure GPIO pin Output Level */
  HAL_GPIO_WritePin(GPIOD, USB_OTG_HS_VBUS_Pin|HUMAN1_Pin|HUMAN2_Pin|HUMAN3_Pin
                          |MPU_SS_Pin|SPI_R_SS_Pin|RS_SIG2_Pin|RS_SIG1_Pin
                          |LTC_SIG_Pin, GPIO_PIN_RESET);

  /*Configure GPIO pin Output Level */
  HAL_GPIO_WritePin(GPIOB, PING_Pin|RS_SIG2B8_Pin|RS_SIG1B9_Pin, GPIO_PIN_RESET);

  /*Configure GPIO pins : FET_BAR_Pin FET_RIGHT_Pin FET_LEFT_Pin FET_RED_Pin */
  GPIO_InitStruct.Pin = FET_BAR_Pin|FET_RIGHT_Pin|FET_LEFT_Pin|FET_RED_Pin;
  GPIO_InitStruct.Mode = GPIO_MODE_OUTPUT_PP;
  GPIO_InitStruct.Pull = GPIO_NOPULL;
  GPIO_InitStruct.Speed = GPIO_SPEED_FREQ_LOW;
  HAL_GPIO_Init(GPIOE, &GPIO_InitStruct);

  /*Configure GPIO pin : FET4_Pin */
  GPIO_InitStruct.Pin = FET4_Pin;
  GPIO_InitStruct.Mode = GPIO_MODE_OUTPUT_PP;
  GPIO_InitStruct.Pull = GPIO_NOPULL;
  GPIO_InitStruct.Speed = GPIO_SPEED_FREQ_VERY_HIGH;
  HAL_GPIO_Init(FET4_GPIO_Port, &GPIO_InitStruct);

  /*Configure GPIO pins : FET3_Pin FET2_Pin FET1_Pin */
  GPIO_InitStruct.Pin = FET3_Pin|FET2_Pin|FET1_Pin;
  GPIO_InitStruct.Mode = GPIO_MODE_OUTPUT_PP;
  GPIO_InitStruct.Pull = GPIO_NOPULL;
  GPIO_InitStruct.Speed = GPIO_SPEED_FREQ_LOW;
  HAL_GPIO_Init(GPIOC, &GPIO_InitStruct);

  /*Configure GPIO pin : EMERGENCY_Pin */
  GPIO_InitStruct.Pin = EMERGENCY_Pin;
  GPIO_InitStruct.Mode = GPIO_MODE_IT_RISING_FALLING;
  GPIO_InitStruct.Pull = GPIO_NOPULL;
  HAL_GPIO_Init(EMERGENCY_GPIO_Port, &GPIO_InitStruct);

  /*Configure GPIO pins : PB14 PB15 */
  GPIO_InitStruct.Pin = GPIO_PIN_14|GPIO_PIN_15;
  GPIO_InitStruct.Mode = GPIO_MODE_AF_PP;
  GPIO_InitStruct.Pull = GPIO_NOPULL;
  GPIO_InitStruct.Speed = GPIO_SPEED_FREQ_VERY_HIGH;
  GPIO_InitStruct.Alternate = GPIO_AF12_OTG_HS_FS;
  HAL_GPIO_Init(GPIOB, &GPIO_InitStruct);

  /*Configure GPIO pins : USB_OTG_HS_VBUS_Pin HUMAN1_Pin HUMAN2_Pin HUMAN3_Pin
                           MPU_SS_Pin SPI_R_SS_Pin RS_SIG2_Pin RS_SIG1_Pin
                           LTC_SIG_Pin */
  GPIO_InitStruct.Pin = USB_OTG_HS_VBUS_Pin|HUMAN1_Pin|HUMAN2_Pin|HUMAN3_Pin
                          |MPU_SS_Pin|SPI_R_SS_Pin|RS_SIG2_Pin|RS_SIG1_Pin
                          |LTC_SIG_Pin;
  GPIO_InitStruct.Mode = GPIO_MODE_OUTPUT_PP;
  GPIO_InitStruct.Pull = GPIO_NOPULL;
  GPIO_InitStruct.Speed = GPIO_SPEED_FREQ_LOW;
  HAL_GPIO_Init(GPIOD, &GPIO_InitStruct);

  /*Configure GPIO pins : PING_Pin RS_SIG2B8_Pin RS_SIG1B9_Pin */
  GPIO_InitStruct.Pin = PING_Pin|RS_SIG2B8_Pin|RS_SIG1B9_Pin;
  GPIO_InitStruct.Mode = GPIO_MODE_OUTPUT_PP;
  GPIO_InitStruct.Pull = GPIO_NOPULL;
  GPIO_InitStruct.Speed = GPIO_SPEED_FREQ_LOW;
  HAL_GPIO_Init(GPIOB, &GPIO_InitStruct);

  /* EXTI interrupt init*/
  HAL_NVIC_SetPriority(EXTI0_IRQn, 2, 0);
  HAL_NVIC_EnableIRQ(EXTI0_IRQn);

}

void StartDefaultTask(void *argument)
{
  /* USER CODE BEGIN 5 */
  /* Infinite loop */
  for(;;)
  {
	osThreadTerminate(defaultTaskHandle);
    osDelay(10000000);
  }
  /* USER CODE END 5 */
}

void HAL_TIM_PeriodElapsedCallback(TIM_HandleTypeDef *htim)
{
  /* USER CODE BEGIN Callback 0 */
  _HAL_TIM_PeriodElapsedCallback(htim);

  /* USER CODE END Callback 0 */
  if (htim->Instance == TIM14) {
    HAL_IncTick();
  }
}

void Error_Handler(void)
{
}

/************************ (C) COPYRIGHT STMicroelectronics *****END OF FILE****/

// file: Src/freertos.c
/* USER CODE BEGIN Header */
/**
  ******************************************************************************
  * File Name          : freertos.c
  * Description        : Code for freertos applications
  ******************************************************************************
  * @attention
  *
  * <h2><center>&copy; Copyright (c) 2019 STMicroelectronics.
  * All rights reserved.</center></h2>
  *
  * This software component is licensed by ST under Ultimate Liberty license
  * SLA0044, the "License"; You may not use this file except in compliance with
  * the License. You may obtain a copy of the License at:
  *                             www.st.com/SLA0044
  *
  ******************************************************************************
  */
/* USER CODE END Header */

#include "FreeRTOS.h"
#include "task.h"
#include "main.h"

/* Hook prototypes */
void vApplicationIdleHook(void);

/* USER CODE BEGIN 2 */
__weak void vApplicationIdleHook( void )
{
   /* vApplicationIdleHook() will only be called if configUSE_IDLE_HOOK is set
   to 1 in FreeRTOSConfig.h. It will be called on each iteration of the idle
   task. It is essential that code added to this hook function never attempts
   to block in any way (for example, call xQueueReceive() with a block time
   specified, or call vTaskDelay()). If the application makes use of the
   vTaskDelete() API function (as this demo application does) then it is also
   important that vApplicationIdleHook() is permitted to return to its calling
   function, because it is the responsibility of the idle task to clean up
   memory allocated by the kernel to any task that has since been deleted. */
}
/* USER CODE END 2 */

/************************ (C) COPYRIGHT STMicroelectronics *****END OF FILE****/
